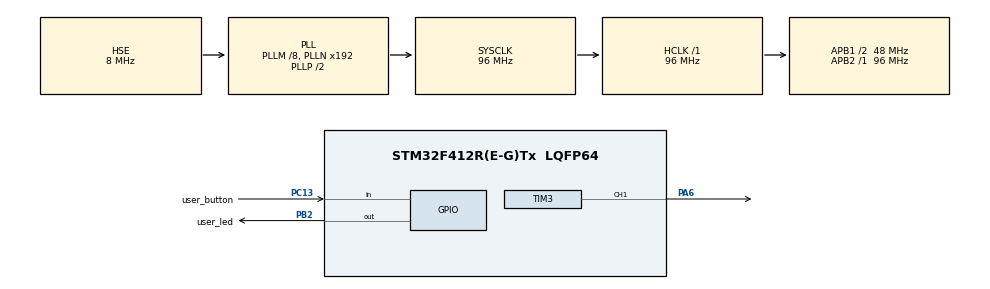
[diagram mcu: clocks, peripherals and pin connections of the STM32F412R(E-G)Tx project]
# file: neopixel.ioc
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Dma.Request0=TIM3_CH1/TRIG
Dma.TIM3_CH1/TRIG.0.Direction=DMA_MEMORY_TO_PERIPH
Dma.TIM3_CH1/TRIG.0.FIFOMode=DMA_FIFOMODE_DISABLE
Dma.TIM3_CH1/TRIG.0.Instance=DMA1_Stream4
Dma.TIM3_CH1/TRIG.0.MemDataAlignment=DMA_MDATAALIGN_HALFWORD
Dma.TIM3_CH1/TRIG.0.MemInc=DMA_MINC_ENABLE
Dma.TIM3_CH1/TRIG.0.Mode=DMA_NORMAL
Dma.TIM3_CH1/TRIG.0.PeriphDataAlignment=DMA_PDATAALIGN_HALFWORD
Dma.TIM3_CH1/TRIG.0.PeriphInc=DMA_PINC_DISABLE
Dma.TIM3_CH1/TRIG.0.Priority=DMA_PRIORITY_HIGH
Mcu.Family=STM32F4
Mcu.Name=STM32F412R(E-G)Tx
Mcu.Package=LQFP64
NVIC.DMA1_Stream4_IRQn=true\:0\:0\:false\:false\:true\:false\:true\:true
NVIC.PriorityGroup=NVIC_PRIORITYGROUP_4
PA13.Mode=Trace_Asynchronous_SW
PA13.Signal=SYS_JTMS-SWDIO
PA14.Mode=Trace_Asynchronous_SW
PA14.Signal=SYS_JTCK-SWCLK
PA6.Signal=S_TIM3_CH1
PB2.GPIO_Label=user_led
PB2.Signal=GPIO_Output
PB3.Mode=Trace_Asynchronous_SW
PB3.Signal=SYS_JTDO-SWO
PC13.GPIO_Label=user_button
PC13.Signal=GPIO_Input
PH0\ -\ OSC_IN.Mode=HSE-External-Oscillator
PH0\ -\ OSC_IN.Signal=RCC_OSC_IN
PH1\ -\ OSC_OUT.Mode=HSE-External-Oscillator
PH1\ -\ OSC_OUT.Signal=RCC_OSC_OUT
ProjectManager.HeapSize=0x200
ProjectManager.StackSize=0x400
ProjectManager.TargetToolchain=STM32CubeIDE
RCC.AHBFreq_Value=96000000
RCC.APB1CLKDivider=RCC_HCLK_DIV2
RCC.APB1Freq_Value=48000000
RCC.APB1TimFreq_Value=96000000
RCC.APB2Freq_Value=96000000
RCC.APB2TimFreq_Value=96000000
RCC.CortexFreq_Value=96000000
RCC.HCLKFreq_Value=96000000
RCC.HSE_VALUE=8000000
RCC.PLLM=8
RCC.PLLSourceVirtual=RCC_PLLSOURCE_HSE
RCC.SYSCLKFreq_VALUE=96000000
RCC.SYSCLKSource=RCC_SYSCLKSOURCE_PLLCLK
RCC.USBFreq_Value=96000000
RCC.VCOOutputFreq_Value=192000000
SH.S_TIM3_CH1.0=TIM3_CH1,PWM Generation1 CH1
TIM3.Channel-PWM\ Generation1\ CH1=TIM_CHANNEL_1
TIM3.OC1Preload_PWM=ENABLE
TIM3.OCMode_PWM-PWM\ Generation1\ CH1=TIM_OCMODE_PWM1
TIM3.Period=120
TIM3.Pulse-PWM\ Generation1\ CH1=39
board=custom

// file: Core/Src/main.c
/* USER CODE BEGIN Header */
/**
  ******************************************************************************
  * @file           : main.c
  * @brief          : Main program body
  ******************************************************************************
  * @attention
  *
  * Copyright (c) 2023 STMicroelectronics.
  * All rights reserved.
  *
  * This software is licensed under terms that can be found in the LICENSE file
  * in the root directory of this software component.
  * If no LICENSE file comes with this software, it is provided AS-IS.
  *
  ******************************************************************************
  */
/* USER CODE END Header */
#include "main.h"
#include "dma.h"
#include "tim.h"
#include "gpio.h"
#include "ws2812.h"

/* USER CODE BEGIN Includes */
//-flto
/* USER CODE END Includes */

void SystemClock_Config(void);

/* USER CODE BEGIN 0 */
volatile ws_tstcolor c = {1,0,0};
volatile uint16_t led = 0;
volatile float mygamma = 1.0f;
volatile int8_t incval = +2;
int8_t inc = 1;
uint16_t d16 = 1;
volatile uint16_t maxval=64*10;

/* USER CODE END 0 */

int main(void)
{

  /* MCU Configuration--------------------------------------------------------*/

  /* Reset of all peripherals, Initializes the Flash interface and the Systick. */
  HAL_Init();

  /* Configure the system clock */
  SystemClock_Config();

  /* Initialize all configured peripherals */
  MX_GPIO_Init();
  MX_DMA_Init();
  MX_TIM3_Init();
  /* USER CODE BEGIN 2 */

  //init leds
  WS_MakeGamma(mygamma);
  WS_Init();

  WS_SendOut();

  //HAL_TIM_PWM_Start(&htim3, TIM_CHANNEL_1);
  //HAL_TIM_PWM_Start_DMA(&htim3, TIM_CHANNEL_1, data, data_size);

  HAL_Delay(100);
  /* USER CODE END 2 */

  /* Infinite loop */
  while (1)
  {

    /* USER CODE BEGIN 3 */
	  //HAL_GPIO_TogglePin(user_led_GPIO_Port,user_led_Pin);
	  HAL_GPIO_WritePin(user_led_GPIO_Port,user_led_Pin,GPIO_PIN_SET);
	 // HAL_TIM_PWM_Start_DMA(&htim3, TIM_CHANNEL_1, data, data_size);
	  WS_Init();
	  //c.r++
//	  c.r+=inc;
//	  if(c.r>=254)inc=-1;
//	  if(c.r<=1)inc=+1;

	  //c.r+=inc;

	 	  if(d16>=(maxval-incval))inc=-incval;
	 	  if(d16<=incval)inc=+incval;
	 	  d16+=inc;

	  WS_MakeGamma(mygamma);

	  //WS_Dither8(c.r);
	  WS_Dither16(d16);
	  /*
	  for(int i=0;i<64;i++){
		  //c.r = i*4+1;
		  WS_SetLed(i, c);
	  }
	  */
	   //WS_SetLed(led, c);
	   //if(++led==64)led=0;
	  WS_SendOut();

	  HAL_Delay(3);
  }
  /* USER CODE END 3 */
}

void SystemClock_Config(void)
{
  RCC_OscInitTypeDef RCC_OscInitStruct = {0};
  RCC_ClkInitTypeDef RCC_ClkInitStruct = {0};

  /** Configure the main internal regulator output voltage
  */
  __HAL_RCC_PWR_CLK_ENABLE();
  __HAL_PWR_VOLTAGESCALING_CONFIG(PWR_REGULATOR_VOLTAGE_SCALE1);

  /** Initializes the RCC Oscillators according to the specified parameters
  * in the RCC_OscInitTypeDef structure.
  */
  RCC_OscInitStruct.OscillatorType = RCC_OSCILLATORTYPE_HSE;
  RCC_OscInitStruct.HSEState = RCC_HSE_ON;
  RCC_OscInitStruct.PLL.PLLState = RCC_PLL_ON;
  RCC_OscInitStruct.PLL.PLLSource = RCC_PLLSOURCE_HSE;
  RCC_OscInitStruct.PLL.PLLM = 8;
  RCC_OscInitStruct.PLL.PLLN = 192;
  RCC_OscInitStruct.PLL.PLLP = RCC_PLLP_DIV2;
  RCC_OscInitStruct.PLL.PLLQ = 2;
  RCC_OscInitStruct.PLL.PLLR = 2;
  if (HAL_RCC_OscConfig(&RCC_OscInitStruct) != HAL_OK)
  {
    Error_Handler();
  }

  /** Initializes the CPU, AHB and APB buses clocks
  */
  RCC_ClkInitStruct.ClockType = RCC_CLOCKTYPE_HCLK|RCC_CLOCKTYPE_SYSCLK
                              |RCC_CLOCKTYPE_PCLK1|RCC_CLOCKTYPE_PCLK2;
  RCC_ClkInitStruct.SYSCLKSource = RCC_SYSCLKSOURCE_PLLCLK;
  RCC_ClkInitStruct.AHBCLKDivider = RCC_SYSCLK_DIV1;
  RCC_ClkInitStruct.APB1CLKDivider = RCC_HCLK_DIV2;
  RCC_ClkInitStruct.APB2CLKDivider = RCC_HCLK_DIV1;

  if (HAL_RCC_ClockConfig(&RCC_ClkInitStruct, FLASH_LATENCY_3) != HAL_OK)
  {
    Error_Handler();
  }
}

void Error_Handler(void)
{
  __disable_irq();
  while (1)
  {
  }
}
